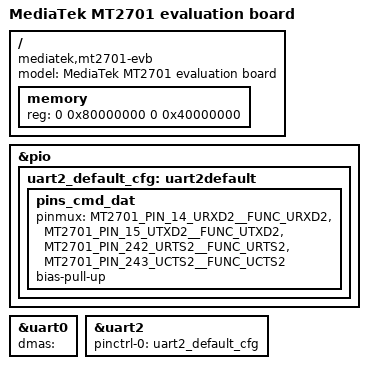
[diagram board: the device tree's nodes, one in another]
/*
 * Copyright (c) 2015 MediaTek Inc.
 * Author: Erin Lo <erin.lo@mediatek.com>
 *
 * This program is free software; you can redistribute it and/or modify
 * it under the terms of the GNU General Public License version 2 as
 * published by the Free Software Foundation.
 *
 * This program is distributed in the hope that it will be useful,
 * but WITHOUT ANY WARRANTY; without even the implied warranty of
 * MERCHANTABILITY or FITNESS FOR A PARTICULAR PURPOSE.  See the
 * GNU General Public License for more details.
 */

/dts-v1/;
#include "mt2701.dtsi"

/ {
	model = "MediaTek MT2701 evaluation board";
	compatible = "mediatek,mt2701-evb", "mediatek,mt2701";

	memory {
		reg = <0 0x80000000 0 0x40000000>;
	};
};

&pio {
	uart2_default_cfg: uart2default {
		pins_cmd_dat {
			pinmux = <MT2701_PIN_14_URXD2__FUNC_URXD2>,
				 <MT2701_PIN_15_UTXD2__FUNC_UTXD2>,
				 <MT2701_PIN_242_URTS2__FUNC_URTS2>,
				 <MT2701_PIN_243_UCTS2__FUNC_UCTS2>;
			bias-pull-up;
		};
	};
};

&uart0 {
	dmas = "";
	dma-names = "";

	status = "okay";
};

&uart2 {
	pinctrl-names = "default";
	pinctrl-0 = <&uart2_default_cfg>;

	status = "okay";
};
